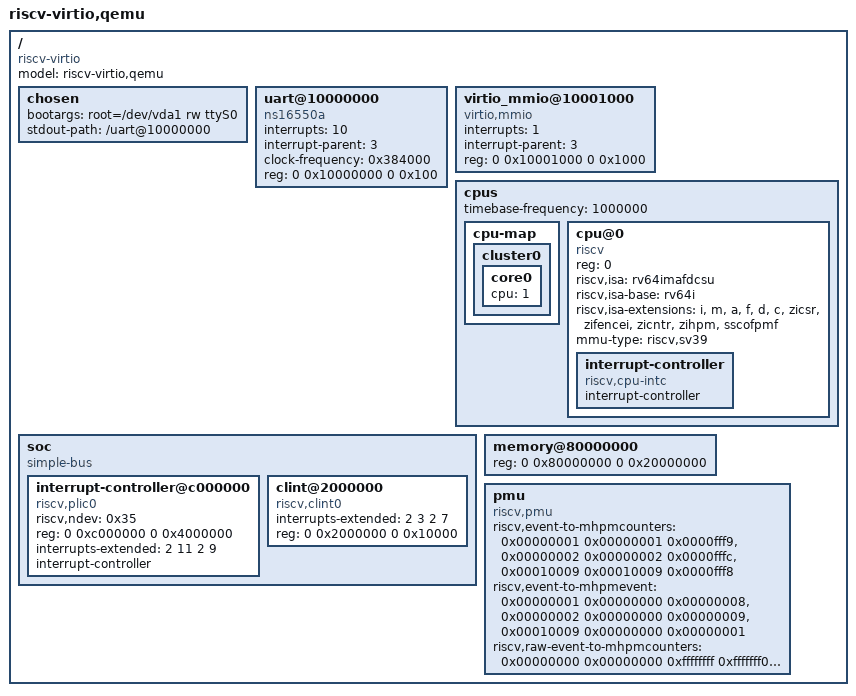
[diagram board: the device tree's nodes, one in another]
/dts-v1/;

/ {
        #address-cells = <2>;
        #size-cells = <2>;
        compatible = "riscv-virtio";
        model = "riscv-virtio,qemu";

        chosen {
                bootargs = "root=/dev/vda1 rw ttyS0";
                stdout-path = "/uart@10000000";
        };

        uart@10000000 {
                interrupts = <10>;
                interrupt-parent = <3>;
                clock-frequency = <0x384000>;
                reg = <0 0x10000000 0 0x100>;
                compatible = "ns16550a";
        };

        virtio_mmio@10001000 {
                interrupts = <1>;
                interrupt-parent = <3>;
                reg = <0 0x10001000 0 0x1000>;
                compatible = "virtio,mmio";
        };

        cpus {
                #address-cells = <1>;
                #size-cells = <0>;
                timebase-frequency = <1000000>; // 1 MHz

                cpu-map {
                        cluster0 {
                                core0 {
                                        cpu = <1>;
                                };
                        };
                };

                cpu@0 {
                        phandle = <1>;
                        device_type = "cpu";
                        reg = <0>;
                        status = "okay";
                        compatible = "riscv";
                        riscv,isa = "rv64imafdcsu";
                        /*
                         * Modern replacement for the deprecated riscv,isa string above
                         * (which Linux warns about and which cannot express multi-letter
                         * extensions). Listing sscofpmf is what lets the kernel arm the
                         * counter-overflow interrupt and accept exclude_user/exclude_kernel
                         * -- without it the PMU driver sets PERF_PMU_CAP_NO_EXCLUDE and
                         * refuses perf record.
                         *
                         * Deliberately omits sstc: simmerv implements it and OpenSBI enables
                         * menvcfg.STCE, but advertising it here would switch the kernel off
                         * the SBI timer, which is a separate change.
                         */
                        riscv,isa-base = "rv64i";
                        riscv,isa-extensions = "i", "m", "a", "f", "d", "c", "zicsr",
                        		       "zifencei", "zicntr", "zihpm", "sscofpmf";
                        mmu-type = "riscv,sv39";

                        interrupt-controller {
                                #interrupt-cells = <1>;
                                interrupt-controller;
                                compatible = "riscv,cpu-intc";
                                phandle = <2>;
                        };
                };
        };

        soc {
                #address-cells = <2>;
                #size-cells = <2>;
                compatible = "simple-bus";
                ranges;

                interrupt-controller@c000000 {
                        phandle = <3>;
                        riscv,ndev = <0x35>;
                        reg = <0 0xc000000 0 0x4000000>;
                        interrupts-extended = <2 11 2 9>;
                        interrupt-controller;
                        compatible = "riscv,plic0";
                        #interrupt-cells = <1>;
                        #address-cells = <0>;
                };

                clint@2000000 {
                        interrupts-extended = <2 3 2 7>;
                        reg = <0 0x2000000 0 0x10000>;
                        compatible = "riscv,clint0";
                };
        };

        memory@80000000 {
                device_type = "memory";
                reg = <0 0x80000000 0 0x20000000>;
        };

	/*
	 * PMU description consumed by OpenSBI (fdt_pmu_setup).  Without it
	 * OpenSBI's hardware-event map is empty and sbi_pmu_event_get_info()
	 * answers "unsupported" for every event -- which Linux >= 7.1 uses
	 * whenever the firmware speaks SBI 3.0, so even cycles and
	 * instructions come back -ENOENT ("<not supported>" in perf stat).
	 *
	 * CPU_CYCLES/INSTRUCTIONS list the programmable counters as well as
	 * their fixed one: mcycle/minstret have no OF or *INH bits (scountovf
	 * has no bits below 3), so OpenSBI steers them to an mhpmcounter when
	 * Sscofpmf is present -- that is what makes perf record and
	 * cycles:u / cycles:k work.  Selectors are csr::HPM_EV_* in
	 * src/csr.rs and must be non-zero or OpenSBI refuses the counter.
	 */
	pmu {
		compatible = "riscv,pmu";

		/* <event_idx_start event_idx_end counter_bitmap> */
		riscv,event-to-mhpmcounters =
			<0x00000001 0x00000001 0x0000fff9>,   /* cycles       */
			<0x00000002 0x00000002 0x0000fffc>,   /* instructions */
			<0x00010009 0x00010009 0x0000fff8>;   /* L1I rd miss  */

		/* <event_idx select_hi select_lo> */
		riscv,event-to-mhpmevent =
			<0x00000001 0x00000000 0x00000008>,
			<0x00000002 0x00000000 0x00000009>,
			<0x00010009 0x00000000 0x00000001>;

		/*
		 * <select_hi select_lo mask_hi mask_lo counter_bitmap>
		 * Raw selectors 0..15 on mhpmcounter3..15:
		 *   r1 uop/bb miss  r2 cold miss  r3 conflict miss
		 *   r4 block hit    r5 flushes    r6 itlb miss  r7 dtlb miss
		 *   r8 cycles       r9 instructions
		 * e.g. "perf stat -e r1,r4 ./prog".
		 */
		riscv,raw-event-to-mhpmcounters =
			<0x00000000 0x00000000 0xffffffff 0xfffffff0 0x0000fff8>;
	};
};
